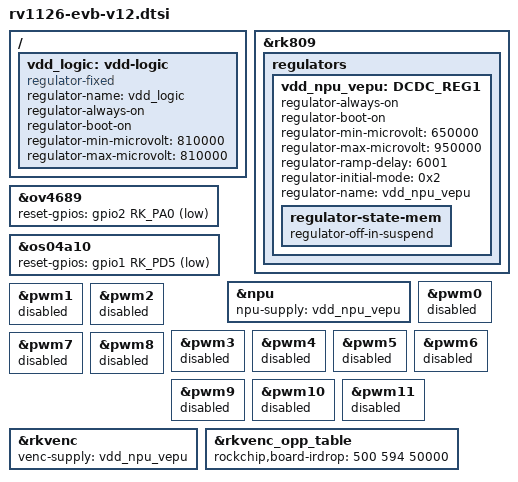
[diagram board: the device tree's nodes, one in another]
// SPDX-License-Identifier: (GPL-2.0+ OR MIT)
/*
 * Copyright (c) 2020 Rockchip Electronics Co., Ltd.
 */

#include "rv1126-evb-v10.dtsi"
/ {
	/delete-node/ vdd-npu;
	/delete-node/ vdd-vepu;

	vdd_logic: vdd-logic {
		compatible = "regulator-fixed";
		regulator-name = "vdd_logic";
		regulator-always-on;
		regulator-boot-on;
		regulator-min-microvolt = <810000>;
		regulator-max-microvolt = <810000>;
	};
};

&rk809 {
	regulators {
		/delete-node/ DCDC_REG1;
		vdd_npu_vepu: DCDC_REG1 {
			regulator-always-on;
			regulator-boot-on;
			regulator-min-microvolt = <650000>;
			regulator-max-microvolt = <950000>;
			regulator-ramp-delay = <6001>;
			regulator-initial-mode = <0x2>;
			regulator-name = "vdd_npu_vepu";
			regulator-state-mem {
				regulator-off-in-suspend;
			};
		};
	};
};

&ov4689 {
	reset-gpios = <&gpio2 RK_PA0 GPIO_ACTIVE_LOW>;
};

&os04a10 {
	reset-gpios = <&gpio1 RK_PD5 GPIO_ACTIVE_LOW>;
};

&npu {
	npu-supply = <&vdd_npu_vepu>;
};

&pwm0 {
	status = "disabled";
};

&pwm1 {
	status = "disabled";
};

//Add by caihz
&pwm2 {
	status = "disabled";
};

&pwm3 {
	status = "disabled";
};

&pwm4 {
	status = "disabled";
};

&pwm5 {
	status = "disabled";
};

&pwm6 {
	status = "disabled";
};

&pwm7 {
	status = "disabled";
};

&pwm8 {
	status = "disabled";
};

&pwm9 {
	status = "disabled";
};

&pwm10 {
	status = "disabled";
};

&pwm11 {
	status = "disabled";
};

//End Add
&rkvenc {
	venc-supply = <&vdd_npu_vepu>;
};

&rkvenc_opp_table {
	/*
	 * max IR-drop values on different freq condition for this board!
	 */
	rockchip,board-irdrop = <
	     /* MHz	MHz	uV */
		500	594	50000
	>;
};
